# NANO103AE_v1 register map
File version: 1.0
Registers are 32-bit, read-write, reset 0x0 unless marked. A register's access mark holds for its fields unless they carry their own. Offsets are from the block's base; [hi:lo] are bit positions; {n}, {i} and the like mark numbered series; 'fields as' and 'values as' point back to an identical list.

## GPIO — GPIO Register Map
Base 0x50004000
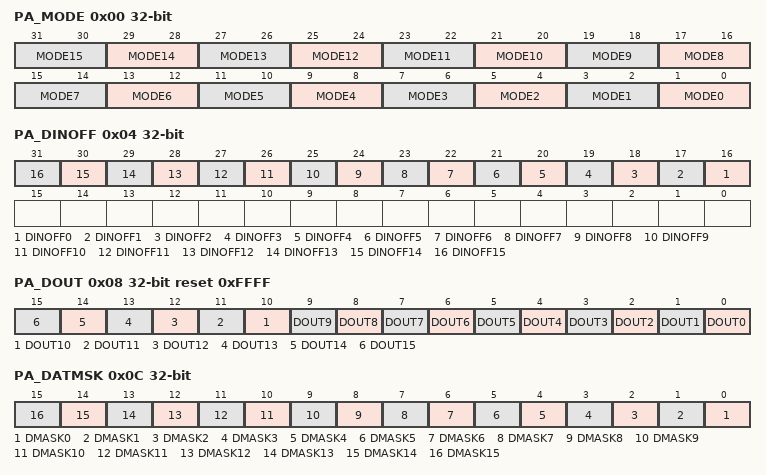
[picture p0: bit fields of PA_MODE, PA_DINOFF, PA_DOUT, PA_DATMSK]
0x00 PA_MODE reset not defined — PA I/O Mode Control
  [all] fields
    0=Px.n is in Input mode; 1=Px.n is in Push-pull Output mode; 2=Px.n is in Open-drain Output mode
  [2n+1:2n] MODE{n} (n=0..15) — Port A-f I/O Pin[N] Mode Control. Determine each I/O mode of Px.n pins. Note2: ThePA.7/PB.12/PC.4/PC.5/PC.12/PC.13/PD.0/PD.1/PD.2/PD.3/PD.4/PD.5/PD.8/PD.9/PD.10/PD.11/PD.12/PD.13/PE.0/PE.1/PE.2/PE.3/PE.4/PE.6/PE.7/PE.8/PE.9/PE.10/PE.11/PE.12/PE.13/PE.14/PE.15/PF.4/PF.5 pin is ignored.
0x04 PA_DINOFF — PA Digital Input Path Disable Control
  [all] fields
    0=Px.n digital input path Enabled; 1=Px.n digital input path Disabled (digital input tied to low)
  [n+16] DINOFF{n} (n=0..15) — Port A-f Pin[N] Digital Input Path Disable Bit. Each of these bits is used to control if the digital input path of corresponding Px.n pin is disabled. If input is analog signal, users can disable Px.n digital input path to avoid input current leakage. Note2: ThePA.7/PB.12/PC.4/PC.5/PC.12/PC.13/PD.0/PD.1/PD.2/PD.3/PD.4/PD.5/PD.8/PD.9/PD.10/PD.11/PD.12/PD.13/PE.0/PE.1/PE.2/PE.3/PE.4/PE.6/PE.7/PE.8/PE.9/PE.10/PE.11/PE.12/PE.13/PE.14/PE.15/PF.4/PF.5 pin is ignored.
0x08 PA_DOUT reset 0xFFFF — PA Data Output Value
  [all] fields
    0=Px.n will drive Low if the Px.n pin is configured as Push-pull output, Open-drain output; 1=Px.n will drive High if the Px.n pin is configured as Push-pull output
  [n] DOUT{n} (n=0..15) — Port A-f Pin[N] Output Value. Each of these bits controls the status of a Px.n pin when the Px.n is configured as Push-pull output, Open-drain output. Note2: ThePA.7/PB.12/PC.4/PC.5/PC.12/PC.13/PD.0/PD.1/PD.2/PD.3/PD.4/PD.5/PD.8/PD.9/PD.10/PD.11/PD.12/PD.13/PE.0/PE.1/PE.2/PE.3/PE.4/PE.6/PE.7/PE.8/PE.9/PE.10/PE.11/PE.12/PE.13/PE.14/PE.15/PF.4/PF.5 pin is ignored.
0x0C PA_DATMSK — PA Data Output Write Mask
  [all] fields
    0=Corresponding DOUT (Px_DOUT[n]) bit can be updated; 1=Corresponding DOUT (Px_DOUT[n]) bit protected
  [n] DMASK{n} (n=0..15) — Port A-f Pin[N] Data Output Write Mask. These bits are used to protect the corresponding DOUT (Px_DOUT[n]) bit. When the DATMSK (Px_DATMSK[n]) bit is set to 1, the corresponding DOUT (Px_DOUT[n]) bit is protected. If the write signal is masked, writing data to the protect bit is ignored. Note3: ThePA.7/PB.12/PC.4/PC.5/PC.12/PC.13/PD.0/PD.1/PD.2/PD.3/PD.4/PD.5/PD.8/PD.9/PD.10/PD.11/PD.12/PD.13/PE.0/PE.1/PE.2/PE.3/PE.4/PE.6/PE.7/PE.8/PE.9/PE.10/PE.11/PE.12/PE.13/PE.14/PE.15/PF.4/PF.5 pin is ignored.
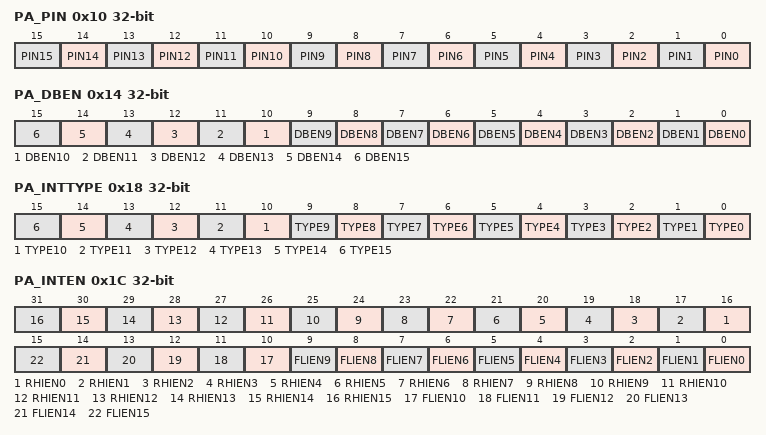
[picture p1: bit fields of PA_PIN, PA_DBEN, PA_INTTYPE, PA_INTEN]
0x10 PA_PIN ro (reset mask 0xFFFF0000) — PA Pin Value
  [n] PIN{n} (n=0..15) — Port A-f Pin[N] Pin Value. Each bit of the register reflects the actual status of the respective Px.n pin. If the bit is 1, it indicates the corresponding pin status is high; else the pin status is low. Note1: Note2: ThePA.7/PB.12/PC.4/PC.5/PC.12/PC.13/PD.0/PD.1/PD.2/PD.3/PD.4/PD.5/PD.8/PD.9/PD.10/PD.11/PD.12/PD.13/PE.0/PE.1/PE.2/PE.3/PE.4/PE.6/PE.7/PE.8/PE.9/PE.10/PE.11/PE.12/PE.13/PE.14/PE.15/PF.4/PF.5 pin is ignored.
0x14 PA_DBEN — PA De-Bounce Enable Control Register
  [all] fields
    0=Px.n de-bounce function Disabled; 1=Px.n de-bounce function Enabled
  [n] DBEN{n} (n=0..15) — Port A-f Pin[N] Input Signal De-bounce Enable Bit. The DBEN[n] bit is used to enable the de-bounce function for each corresponding bit. If the input signal pulse width cannot be sampled by continuous two de-bounce sample cycle, the input signal transition is seen as the signal bounce and will not trigger the interrupt. The de-bounce clock source is controlled by DBCLKSRC (GPIO_DBCTL [4]), one de-bounce sample cycle period is controlled by DBCLKSEL (GPIO_DBCTL [3:0]). Note2: ThePA.7/PB.12/PC.4/PC.5/PC.12/PC.13/PD.0/PD.1/PD.2/PD.3/PD.4/PD.5/PD.8/PD.9/PD.10/PD.11/PD.12/PD.13/PE.0/PE.1/PE.2/PE.3/PE.4/PE.6/PE.7/PE.8/PE.9/PE.10/PE.11/PE.12/PE.13/PE.14/PE.15/PF.4/PF.5 pin is ignored.
0x18 PA_INTTYPE — PA Interrupt Trigger Type Control
  [all] fields
    0=Edge trigger interrupt; 1=Level trigger interrupt
  [n] TYPE{n} (n=0..15) — Port A-f Pin[N] Edge or Level Detection Interrupt Trigger Type Control. TYPE (Px_INTTYPE[n]) bit is used to control the triggered interrupt is by level trigger or by edge trigger. If the interrupt is by edge trigger, the trigger source can be controlled by de-bounce. If the interrupt is by level trigger, the input source is sampled by one HCLK clock and generates the interrupt. Note2: ThePA.7/PB.12/PC.4/PC.5/PC.12/PC.13/PD.0/PD.1/PD.2/PD.3/PD.4/PD.5/PD.8/PD.9/PD.10/PD.11/PD.12/PD.13/PE.0/PE.1/PE.2/PE.3/PE.4/PE.6/PE.7/PE.8/PE.9/PE.10/PE.11/PE.12/PE.13/PE.14/PE.15/PF.4/PF.5 pin is ignored.
0x1C PA_INTEN — PA Interrupt Enable Control Register
  [n+16] RHIEN{n} (n=0..15) — Port A-f Pin[N] Rising Edge or High Level Interrupt Trigger Type Enable Bit. The RHIEN (Px_INTEN[n+16]) bit is used to enable the interrupt for each of the corresponding input Px.n pin. Set bit to 1 also enable the pin wake-up function. When setting the RHIEN (Px_INTEN[n+16]) bit to 1 : If the interrupt is level trigger (TYPE (Px_INTTYPE[n]) bit is set to 1), the input Px.n pin will generate the interrupt while this pin state is at high level. If the interrupt is edge trigger (TYPE (Px_INTTYPE[n]) bit is set to 0), the input Px.n pin will generate the interrupt while this pin state changed from low to high. Note2: ThePA.7/PB.12/PC.4/PC.5/PC.12/PC.13/PD.0/PD.1/PD.2/PD.3/PD.4/PD.5/PD.8/PD.9/PD.10/PD.11/PD.12/PD.13/PE.0/PE.1/PE.2/PE.3/PE.4/PE.6/PE.7/PE.8/PE.9/PE.10/PE.11/PE.12/PE.13/PE.14/PE.15/PF.4/PF.5 pin is ignored.
    0=Px.n level high or low to high interrupt Disabled; 1=Px.n level high or low to high interrupt Enabled
  [n] FLIEN{n} (n=0..15) — Port A-f Pin[N] Falling Edge or Low Level Interrupt Trigger Type Enable Bit. The FLIEN (Px_INTEN[n]) bit is used to enable the interrupt for each of the corresponding input Px.n pin. Set bit to 1 also enable the pin wake-up function. When setting the FLIEN (Px_INTEN[n]) bit to 1 : If the interrupt is level trigger (TYPE (Px_INTTYPE[n]) bit is set to 1), the input Px.n pin will generate the interrupt while this pin state is at low level. If the interrupt is edge trigger(TYPE (Px_INTTYPE[n]) bit is set to 0), the input Px.n pin will generate the interrupt while this pin state changed from high to low. Note2: ThePA.7/PB.12/PC.4/PC.5/PC.12/PC.13/PD.0/PD.1/PD.2/PD.3/PD.4/PD.5/PD.8/PD.9/PD.10/PD.11/PD.12/PD.13/PE.0/PE.1/PE.2/PE.3/PE.4/PE.6/PE.7/PE.8/PE.9/PE.10/PE.11/PE.12/PE.13/PE.14/PE.15/PF.4/PF.5 pin is ignored.
    0=Px.n level low or high to low interrupt Disabled; 1=Px.n level low or high to low interrupt Enabled
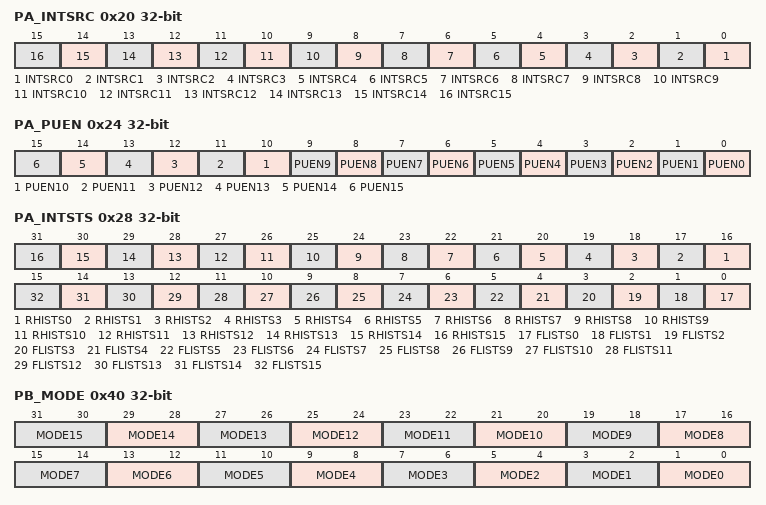
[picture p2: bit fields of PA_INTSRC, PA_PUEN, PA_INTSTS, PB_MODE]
0x20 PA_INTSRC (reset mask 0xFFFF0000) — PA Interrupt Source Flag
  [all] fields
    0=No action. No interrupt at Px.n; 1=Clear the corresponding pending interrupt. Px.n generates an interrupt
  [n] INTSRC{n} (n=0..15) — Port A-f Pin[N] Interrupt Source Flag. Write Operation : Note2: ThePA.7/PB.12/PC.4/PC.5/PC.12/PC.13/PD.0/PD.1/PD.2/PD.3/PD.4/PD.5/PD.8/PD.9/PD.10/PD.11/PD.12/PD.13/PE.0/PE.1/PE.2/PE.3/PE.4/PE.6/PE.7/PE.8/PE.9/PE.10/PE.11/PE.12/PE.13/PE.14/PE.15/PF.4/PF.5 pin is ignored.
0x24 PA_PUEN — PA Pull-Up Enable Control Register
  [all] fields
    0=Px.n internal pull-up resistor Disabled; 1=Px.n internal pull-up resistor Enabled
  [n] PUEN{n} (n=0..15) — Port A-f Pin[N]Pull-up Enable Bit. Read : Note2: ThePA.7/PB.12/PC.4/PC.5/PC.12/PC.13/PD.0/PD.1/PD.2/PD.3/PD.4/PD.5/PD.8/PD.9/PD.10/PD.11/PD.12/PD.13/PE.0/PE.1/PE.2/PE.3/PE.4/PE.6/PE.7/PE.8/PE.9/PE.10/PE.11/PE.12/PE.13/PE.14/PE.15/PF.4/PF.5 pin is ignored.
0x28 PA_INTSTS ro — PA Interrupt Status
  [n+16] RHISTS{n} (n=0..15) — Port A-f Pin[N] Rising Edge Interrupt Status. If the interrupt is rising edge trigger for each of the corresponding input Px.n pin, this bit will be set after interrupt occurred and automatically cleared by interrupt source flag (INTSRC (Px_INTSRC[n])). Note2: The PA.7/PB.12/PC.4/PC.5/PC.12/PC.13/PD.0/PD.1/PD.2/PD.3/PD.4/PD.5/PD.8/PD.9/PD.10/PD.11/PD.12/PD.13/PE.0/PE.1/PE.2/PE.3/PE.4/PE.6/PE.7/PE.8/PE.9/PE.10/PE.11/PE.12/PE.13/PE.14/PE.15/PF.4/PF.5 pin is ignored.
    0=No rising edge interrupt at Px.n; 1=Px.n generates an rising edge interrupt
  [n] FLISTS{n} (n=0..15) — Port A-f Pin[N] Falling Edge Interrupt Status. If the interrupt is falling edge trigger for each of the corresponding input Px.n pin, this bit will be set after interrupt occurred and automatically cleared by interrupt source flag (INTSRC (Px_INTSRC[n])). Note2: The PA.7/PB.12/PC.4/PC.5/PC.12/PC.13/PD.0/PD.1/PD.2/PD.3/PD.4/PD.5/PD.8/PD.9/PD.10/PD.11/PD.12/PD.13/PE.0/PE.1/PE.2/PE.3/PE.4/PE.6/PE.7/PE.8/PE.9/PE.10/PE.11/PE.12/PE.13/PE.14/PE.15/PF.4/PF.5 pin is ignored.
    0=No falling edge interrupt at Px.n; 1=Px.n generates an falling edge interrupt
0x40 PB_MODE reset not defined — PB I/O Mode Control
  fields as PA_MODE
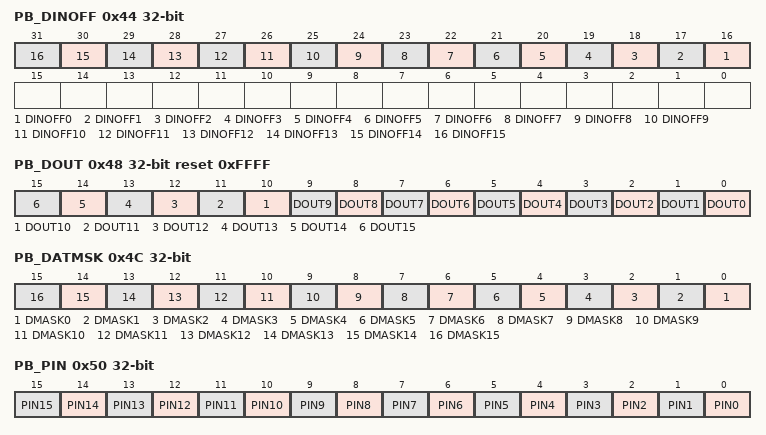
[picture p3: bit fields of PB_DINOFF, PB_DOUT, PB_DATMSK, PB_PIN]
0x44 PB_DINOFF — PB Digital Input Path Disable Control
  fields as PA_DINOFF
0x48 PB_DOUT reset 0xFFFF — PB Data Output Value
  fields as PA_DOUT
0x4C PB_DATMSK — PB Data Output Write Mask
  fields as PA_DATMSK
0x50 PB_PIN ro (reset mask 0xFFFF0000) — PB Pin Value
  fields as PA_PIN
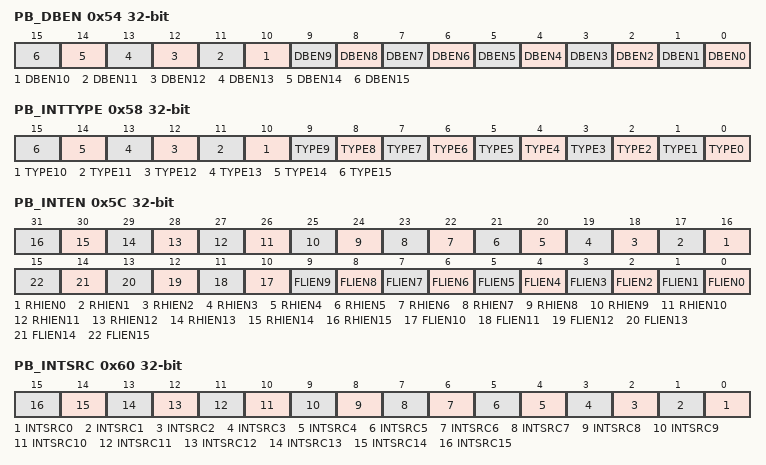
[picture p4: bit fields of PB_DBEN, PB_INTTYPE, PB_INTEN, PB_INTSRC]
0x54 PB_DBEN — PB De-Bounce Enable Control Register
  fields as PA_DBEN
0x58 PB_INTTYPE — PB Interrupt Trigger Type Control
  fields as PA_INTTYPE
0x5C PB_INTEN — PB Interrupt Enable Control Register
  fields as PA_INTEN
0x60 PB_INTSRC (reset mask 0xFFFF0000) — PB Interrupt Source Flag
  fields as PA_INTSRC
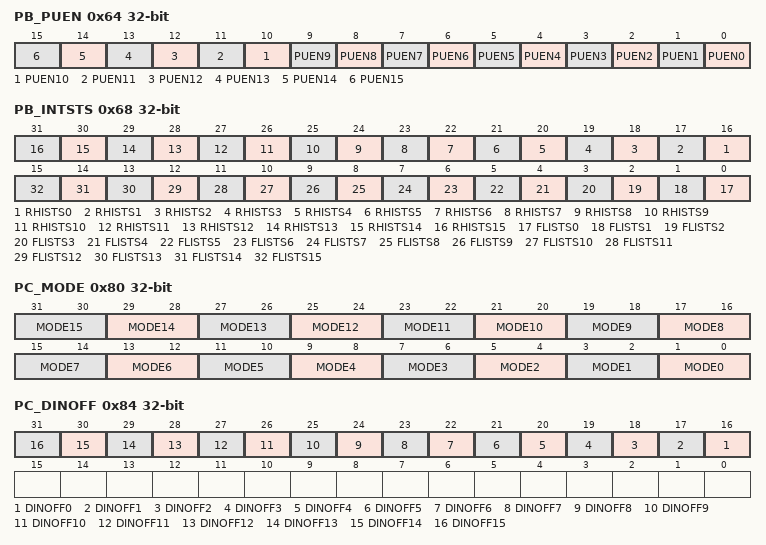
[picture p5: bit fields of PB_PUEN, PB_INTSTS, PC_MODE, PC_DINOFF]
0x64 PB_PUEN — PB Pull-Up Enable Control Register
  fields as PA_PUEN
0x68 PB_INTSTS ro — PB Interrupt Status
  fields as PA_INTSTS
0x80 PC_MODE reset not defined — PC I/O Mode Control
  fields as PA_MODE
0x84 PC_DINOFF — PC Digital Input Path Disable Control
  fields as PA_DINOFF
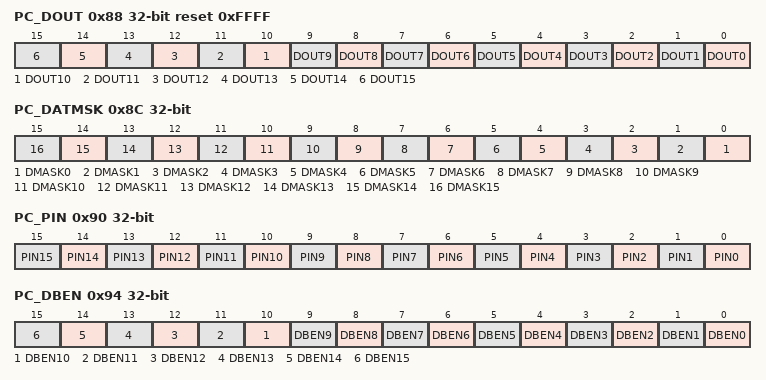
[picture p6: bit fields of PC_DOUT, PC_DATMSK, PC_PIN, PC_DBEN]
0x88 PC_DOUT reset 0xFFFF — PC Data Output Value
  fields as PA_DOUT
0x8C PC_DATMSK — PC Data Output Write Mask
  fields as PA_DATMSK
0x90 PC_PIN ro (reset mask 0xFFFF0000) — PC Pin Value
  fields as PA_PIN
0x94 PC_DBEN — PC De-Bounce Enable Control Register
  fields as PA_DBEN
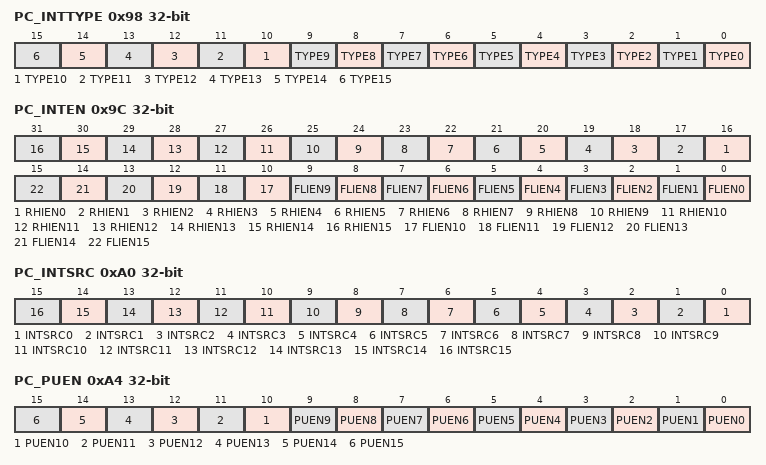
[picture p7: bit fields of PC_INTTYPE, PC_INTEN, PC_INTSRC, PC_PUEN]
0x98 PC_INTTYPE — PC Interrupt Trigger Type Control
  fields as PA_INTTYPE
0x9C PC_INTEN — PC Interrupt Enable Control Register
  fields as PA_INTEN
0xA0 PC_INTSRC (reset mask 0xFFFF0000) — PC Interrupt Source Flag
  fields as PA_INTSRC
0xA4 PC_PUEN — PC Pull-Up Enable Control Register
  fields as PA_PUEN
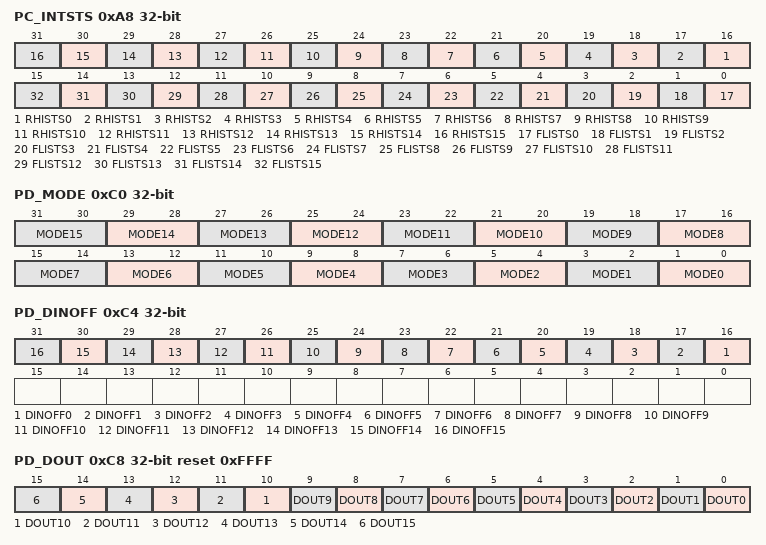
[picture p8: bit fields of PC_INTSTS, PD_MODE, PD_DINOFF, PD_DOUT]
0xA8 PC_INTSTS ro — PC Interrupt Status
  fields as PA_INTSTS
0xC0 PD_MODE reset not defined — PD I/O Mode Control
  fields as PA_MODE
0xC4 PD_DINOFF — PD Digital Input Path Disable Control
  fields as PA_DINOFF
0xC8 PD_DOUT reset 0xFFFF — PD Data Output Value
  fields as PA_DOUT
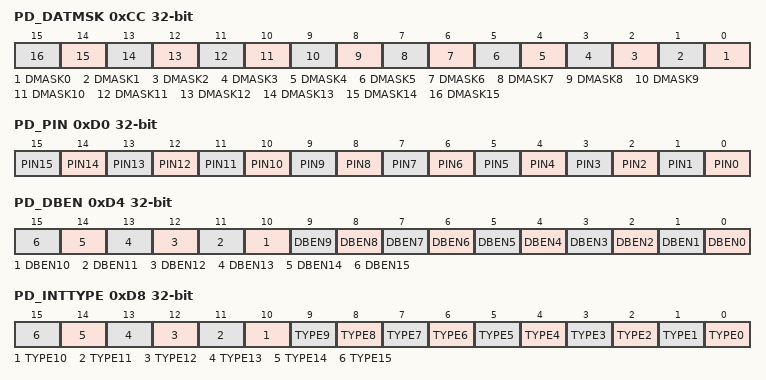
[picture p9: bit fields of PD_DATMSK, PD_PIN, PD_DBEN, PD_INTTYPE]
0xCC PD_DATMSK — PD Data Output Write Mask
  fields as PA_DATMSK
0xD0 PD_PIN ro (reset mask 0xFFFF0000) — PD Pin Value
  fields as PA_PIN
0xD4 PD_DBEN — PD De-Bounce Enable Control Register
  fields as PA_DBEN
0xD8 PD_INTTYPE — PD Interrupt Trigger Type Control
  fields as PA_INTTYPE
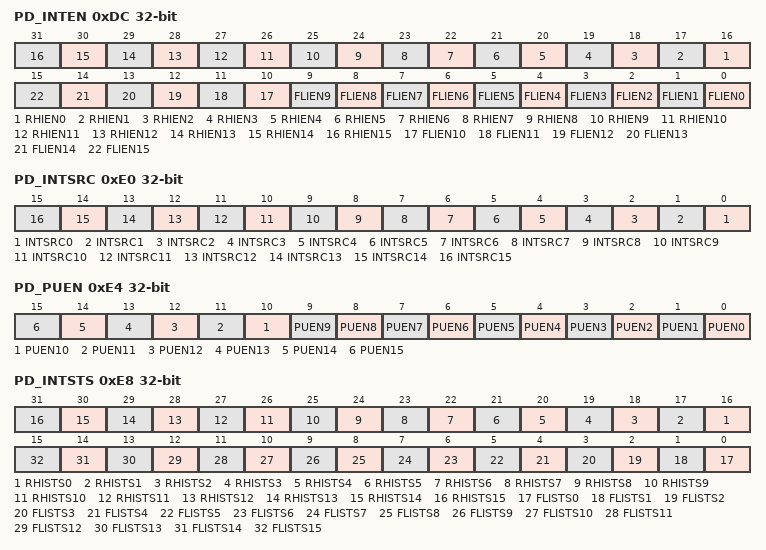
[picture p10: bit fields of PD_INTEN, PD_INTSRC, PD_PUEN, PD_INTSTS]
0xDC PD_INTEN — PD Interrupt Enable Control Register
  fields as PA_INTEN
0xE0 PD_INTSRC (reset mask 0xFFFF0000) — PD Interrupt Source Flag
  fields as PA_INTSRC
0xE4 PD_PUEN — PD Pull-Up Enable Control Register
  fields as PA_PUEN
0xE8 PD_INTSTS ro — PD Interrupt Status
  fields as PA_INTSTS
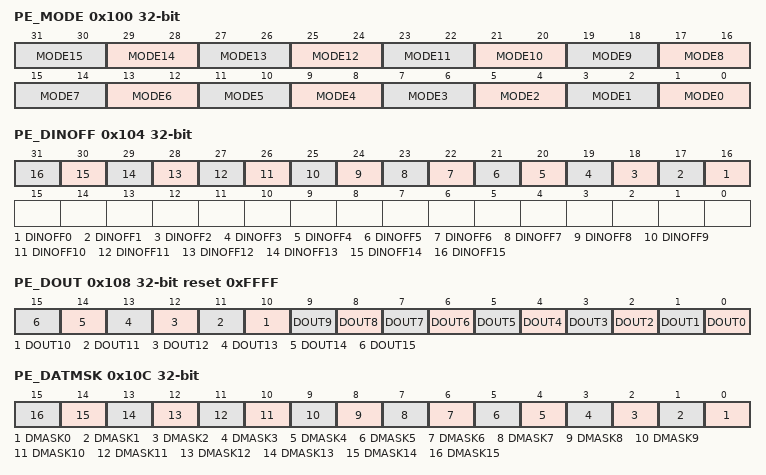
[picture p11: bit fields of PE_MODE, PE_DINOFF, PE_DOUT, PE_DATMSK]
0x100 PE_MODE reset not defined — PE I/O Mode Control
  fields as PA_MODE
0x104 PE_DINOFF — PE Digital Input Path Disable Control
  fields as PA_DINOFF
0x108 PE_DOUT reset 0xFFFF — PE Data Output Value
  fields as PA_DOUT
0x10C PE_DATMSK — PE Data Output Write Mask
  fields as PA_DATMSK
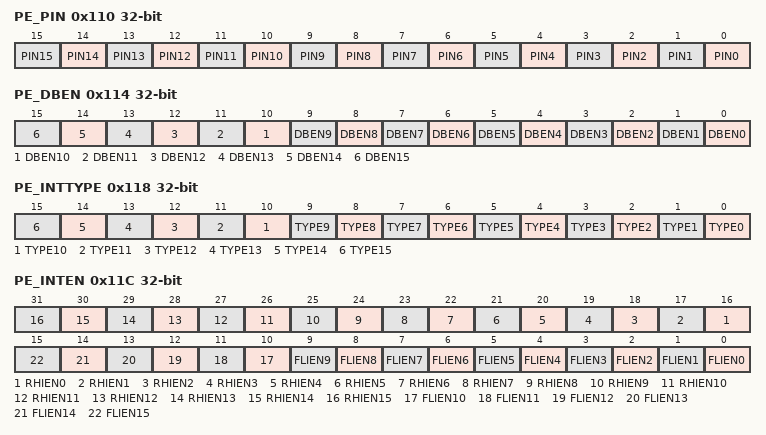
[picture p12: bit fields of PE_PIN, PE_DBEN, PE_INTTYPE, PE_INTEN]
0x110 PE_PIN ro (reset mask 0xFFFF0000) — PE Pin Value
  fields as PA_PIN
0x114 PE_DBEN — PE De-Bounce Enable Control Register
  fields as PA_DBEN
0x118 PE_INTTYPE — PE Interrupt Trigger Type Control
  fields as PA_INTTYPE
0x11C PE_INTEN — PE Interrupt Enable Control Register
  fields as PA_INTEN
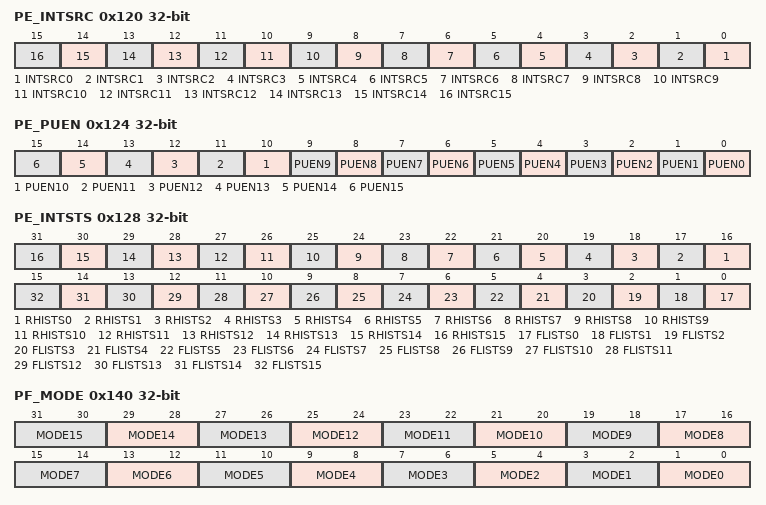
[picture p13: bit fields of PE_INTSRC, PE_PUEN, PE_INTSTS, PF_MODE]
0x120 PE_INTSRC (reset mask 0xFFFF0000) — PE Interrupt Source Flag
  fields as PA_INTSRC
0x124 PE_PUEN — PE Pull-Up Enable Control Register
  fields as PA_PUEN
0x128 PE_INTSTS ro — PE Interrupt Status
  fields as PA_INTSTS
0x140 PF_MODE reset not defined — PF I/O Mode Control
  fields as PA_MODE
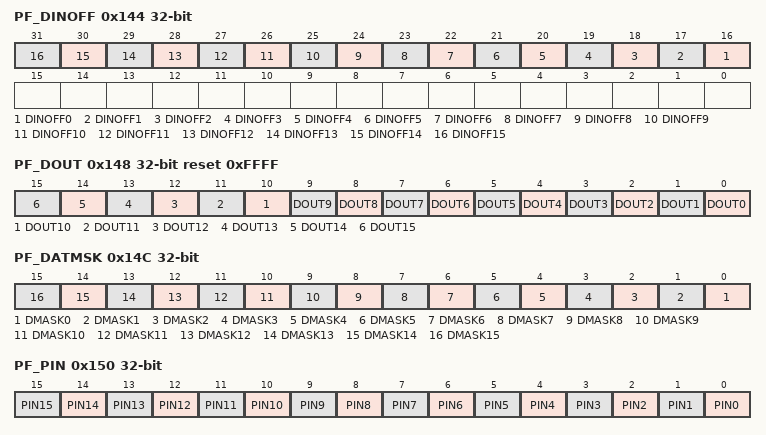
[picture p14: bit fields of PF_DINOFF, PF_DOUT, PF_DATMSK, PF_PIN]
0x144 PF_DINOFF — PF Digital Input Path Disable Control
  fields as PA_DINOFF
0x148 PF_DOUT reset 0xFFFF — PF Data Output Value
  fields as PA_DOUT
0x14C PF_DATMSK — PF Data Output Write Mask
  fields as PA_DATMSK
0x150 PF_PIN ro (reset mask 0xFFFF0000) — PF Pin Value
  fields as PA_PIN
0x154 PF_DBEN — PF De-Bounce Enable Control Register
  fields as PA_DBEN
0x158 PF_INTTYPE — PF Interrupt Trigger Type Control
  fields as PA_INTTYPE
0x15C PF_INTEN — PF Interrupt Enable Control Register
  fields as PA_INTEN
0x160 PF_INTSRC (reset mask 0xFFFF0000) — PF Interrupt Source Flag
  fields as PA_INTSRC
0x164 PF_PUEN — PF Pull-Up Enable Control Register
  fields as PA_PUEN
0x168 PF_INTSTS ro — PF Interrupt Status
  fields as PA_INTSTS
0x180 GPIO_DBCTL — Interrupt De-bounce Control Register
  [5] ICLKON — Interrupt Clock on Mode. Note:It is recommended to disable this bit to save system power if no special application concern.
    0=Edge detection circuit is active only if I/O pin corresponding RHIEN (Px_INTEN[n+16])/FLIEN (Px_INTEN[n]) bit is set to 1; 1=All I/O pins edge detection circuit is always active after reset
  [4] DBCLKSRC — De-bounce Counter Clock Source Selection
    0=De-bounce counter clock source is the HCLK; 1=De-bounce counter clock source is the 10 kHz internal low speed RC oscillator (LIRC)
  [3:0] DBCLKSEL — De-bounce Sampling Cycle Selection
    0=Sample interrupt input once per 1 clocks; 1=Sample interrupt input once per 2 clocks; 2=Sample interrupt input once per 4 clocks; 3=Sample interrupt input once per 8 clocks; 4=Sample interrupt input once per 16 clocks; 5=Sample interrupt input once per 32 clocks; 6=Sample interrupt input once per 64 clocks; 7=Sample interrupt input once per 128 clocks; 8=Sample interrupt input once per 256 clocks; 9=Sample interrupt input once per 2*256 clocks; 10=Sample interrupt input once per 4*256 clocks; 11=Sample interrupt input once per 8*256 clocks; 12=Sample interrupt input once per 16*256 clocks; 13=Sample interrupt input once per 32*256 clocks; 14=Sample interrupt input once per 64*256 clocks; 15=Sample interrupt input once per 128*256 clocks
0x200 PA0_PDIO (reset mask 0xFFFFFFF0) — GPIO PA.0 Pin Data Input/Output Register
  [0] PDIO — GPIO Px.N Pin Data Input/Output. Writing this bit can control one GPIO pin output value. Note3: ThePA.7/PB.12/PC.4/PC.5/PC.12/PC.13/PD.0/PD.1/PD.2/PD.3/PD.4/PD.5/PD.8/PD.9/PD.10/PD.11/PD.12/PD.13/PE.0/PE.1/PE.2/PE.3/PE.4/PE.6/PE.7/PE.8/PE.9/PE.10/PE.11/PE.12/PE.13/PE.14/PE.15/PF.4/PF.5 pin is ignored.
    0=Corresponding GPIO pin set to low; 1=Corresponding GPIO pin set to high
0x204 PA1_PDIO (reset mask 0xFFFFFFF0) — GPIO PA.1 Pin Data Input/Output Register
  fields as PA0_PDIO
0x208 PA2_PDIO (reset mask 0xFFFFFFF0) — GPIO PA.2 Pin Data Input/Output Register
  fields as PA0_PDIO
0x20C PA3_PDIO (reset mask 0xFFFFFFF0) — GPIO PA.3 Pin Data Input/Output Register
  fields as PA0_PDIO
0x210 PA4_PDIO (reset mask 0xFFFFFFF0) — GPIO PA.4 Pin Data Input/Output Register
  fields as PA0_PDIO
0x214 PA5_PDIO (reset mask 0xFFFFFFF0) — GPIO PA.5 Pin Data Input/Output Register
  fields as PA0_PDIO
0x218 PA6_PDIO (reset mask 0xFFFFFFF0) — GPIO PA.6 Pin Data Input/Output Register
  fields as PA0_PDIO
0x21C PA7_PDIO (reset mask 0xFFFFFFF0) — GPIO PA.7 Pin Data Input/Output Register
  fields as PA0_PDIO
0x220 PA8_PDIO (reset mask 0xFFFFFFF0) — GPIO PA.8 Pin Data Input/Output Register
  fields as PA0_PDIO
0x224 PA9_PDIO (reset mask 0xFFFFFFF0) — GPIO PA.9 Pin Data Input/Output Register
  fields as PA0_PDIO
0x228 PA10_PDIO (reset mask 0xFFFFFFF0) — GPIO PA.10 Pin Data Input/Output Register
  fields as PA0_PDIO
0x22C PA11_PDIO (reset mask 0xFFFFFFF0) — GPIO PA.11 Pin Data Input/Output Register
  fields as PA0_PDIO
0x230 PA12_PDIO (reset mask 0xFFFFFFF0) — GPIO PA.12 Pin Data Input/Output Register
  fields as PA0_PDIO
0x234 PA13_PDIO (reset mask 0xFFFFFFF0) — GPIO PA.13 Pin Data Input/Output Register
  fields as PA0_PDIO
0x238 PA14_PDIO (reset mask 0xFFFFFFF0) — GPIO PA.14 Pin Data Input/Output Register
  fields as PA0_PDIO
0x23C PA15_PDIO (reset mask 0xFFFFFFF0) — GPIO PA.15 Pin Data Input/Output Register
  fields as PA0_PDIO
0x240 PB0_PDIO (reset mask 0xFFFFFFF0) — GPIO PB.0 Pin Data Input/Output Register
  fields as PA0_PDIO
0x244 PB1_PDIO (reset mask 0xFFFFFFF0) — GPIO PB.1 Pin Data Input/Output Register
  fields as PA0_PDIO
0x248 PB2_PDIO (reset mask 0xFFFFFFF0) — GPIO PB.2 Pin Data Input/Output Register
  fields as PA0_PDIO
0x24C PB3_PDIO (reset mask 0xFFFFFFF0) — GPIO PB.3 Pin Data Input/Output Register
  fields as PA0_PDIO
0x250 PB4_PDIO (reset mask 0xFFFFFFF0) — GPIO PB.4 Pin Data Input/Output Register
  fields as PA0_PDIO
0x254 PB5_PDIO (reset mask 0xFFFFFFF0) — GPIO PB.5 Pin Data Input/Output Register
  fields as PA0_PDIO
0x258 PB6_PDIO (reset mask 0xFFFFFFF0) — GPIO PB.6 Pin Data Input/Output Register
  fields as PA0_PDIO
0x25C PB7_PDIO (reset mask 0xFFFFFFF0) — GPIO PB.7 Pin Data Input/Output Register
  fields as PA0_PDIO
0x260 PB8_PDIO (reset mask 0xFFFFFFF0) — GPIO PB.8 Pin Data Input/Output Register
  fields as PA0_PDIO
0x264 PB9_PDIO (reset mask 0xFFFFFFF0) — GPIO PB.9 Pin Data Input/Output Register
  fields as PA0_PDIO
0x268 PB10_PDIO (reset mask 0xFFFFFFF0) — GPIO PB.10 Pin Data Input/Output Register
  fields as PA0_PDIO
0x26C PB11_PDIO (reset mask 0xFFFFFFF0) — GPIO PB.11 Pin Data Input/Output Register
  fields as PA0_PDIO
0x270 PB12_PDIO (reset mask 0xFFFFFFF0) — GPIO PB.12 Pin Data Input/Output Register
  fields as PA0_PDIO
0x274 PB13_PDIO (reset mask 0xFFFFFFF0) — GPIO PB.13 Pin Data Input/Output Register
  fields as PA0_PDIO
0x278 PB14_PDIO (reset mask 0xFFFFFFF0) — GPIO PB.14 Pin Data Input/Output Register
  fields as PA0_PDIO
0x27C PB15_PDIO (reset mask 0xFFFFFFF0) — GPIO PB.15 Pin Data Input/Output Register
  fields as PA0_PDIO
0x280 PC0_PDIO (reset mask 0xFFFFFFF0) — GPIO PC.0 Pin Data Input/Output Register
  fields as PA0_PDIO
0x284 PC1_PDIO (reset mask 0xFFFFFFF0) — GPIO PC.1 Pin Data Input/Output Register
  fields as PA0_PDIO
0x288 PC2_PDIO (reset mask 0xFFFFFFF0) — GPIO PC.2 Pin Data Input/Output Register
  fields as PA0_PDIO
0x28C PC3_PDIO (reset mask 0xFFFFFFF0) — GPIO PC.3 Pin Data Input/Output Register
  fields as PA0_PDIO
0x290 PC4_PDIO (reset mask 0xFFFFFFF0) — GPIO PC.4 Pin Data Input/Output Register
  fields as PA0_PDIO
0x294 PC5_PDIO (reset mask 0xFFFFFFF0) — GPIO PC.5 Pin Data Input/Output Register
  fields as PA0_PDIO
0x298 PC6_PDIO (reset mask 0xFFFFFFF0) — GPIO PC.6 Pin Data Input/Output Register
  fields as PA0_PDIO
0x29C PC7_PDIO (reset mask 0xFFFFFFF0) — GPIO PC.7 Pin Data Input/Output Register
  fields as PA0_PDIO
0x2A0 PC8_PDIO (reset mask 0xFFFFFFF0) — GPIO PC.8 Pin Data Input/Output Register
  fields as PA0_PDIO
0x2A4 PC9_PDIO (reset mask 0xFFFFFFF0) — GPIO PC.9 Pin Data Input/Output Register
  fields as PA0_PDIO
0x2A8 PC10_PDIO (reset mask 0xFFFFFFF0) — GPIO PC.10 Pin Data Input/Output Register
  fields as PA0_PDIO
0x2AC PC11_PDIO (reset mask 0xFFFFFFF0) — GPIO PC.11 Pin Data Input/Output Register
  fields as PA0_PDIO
0x2B0 PC12_PDIO (reset mask 0xFFFFFFF0) — GPIO PC.12 Pin Data Input/Output Register
  fields as PA0_PDIO
0x2B4 PC13_PDIO (reset mask 0xFFFFFFF0) — GPIO PC.13 Pin Data Input/Output Register
  fields as PA0_PDIO
0x2B8 PC14_PDIO (reset mask 0xFFFFFFF0) — GPIO PC.14 Pin Data Input/Output Register
  fields as PA0_PDIO
0x2BC PC15_PDIO (reset mask 0xFFFFFFF0) — GPIO PC.15 Pin Data Input/Output Register
  fields as PA0_PDIO
0x2C0 PD0_PDIO (reset mask 0xFFFFFFF0) — GPIO PD.0 Pin Data Input/Output Register
  fields as PA0_PDIO
0x2C4 PD1_PDIO (reset mask 0xFFFFFFF0) — GPIO PD.1 Pin Data Input/Output Register
  fields as PA0_PDIO
0x2C8 PD2_PDIO (reset mask 0xFFFFFFF0) — GPIO PD.2 Pin Data Input/Output Register
  fields as PA0_PDIO
0x2CC PD3_PDIO (reset mask 0xFFFFFFF0) — GPIO PD.3 Pin Data Input/Output Register
  fields as PA0_PDIO
0x2D0 PD4_PDIO (reset mask 0xFFFFFFF0) — GPIO PD.4 Pin Data Input/Output Register
  fields as PA0_PDIO
0x2D4 PD5_PDIO (reset mask 0xFFFFFFF0) — GPIO PD.5 Pin Data Input/Output Register
  fields as PA0_PDIO
0x2D8 PD6_PDIO (reset mask 0xFFFFFFF0) — GPIO PD.6 Pin Data Input/Output Register
  fields as PA0_PDIO
0x2DC PD7_PDIO (reset mask 0xFFFFFFF0) — GPIO PD.7 Pin Data Input/Output Register
  fields as PA0_PDIO
0x2E0 PD8_PDIO (reset mask 0xFFFFFFF0) — GPIO PD.8 Pin Data Input/Output Register
  fields as PA0_PDIO
0x2E4 PD9_PDIO (reset mask 0xFFFFFFF0) — GPIO PD.9 Pin Data Input/Output Register
  fields as PA0_PDIO
0x2E8 PD10_PDIO (reset mask 0xFFFFFFF0) — GPIO PD.10 Pin Data Input/Output Register
  fields as PA0_PDIO
0x2EC PD11_PDIO (reset mask 0xFFFFFFF0) — GPIO PD.11 Pin Data Input/Output Register
  fields as PA0_PDIO
0x2F0 PD12_PDIO (reset mask 0xFFFFFFF0) — GPIO PD.12 Pin Data Input/Output Register
  fields as PA0_PDIO
0x2F4 PD13_PDIO (reset mask 0xFFFFFFF0) — GPIO PD.13 Pin Data Input/Output Register
  fields as PA0_PDIO
0x2F8 PD14_PDIO (reset mask 0xFFFFFFF0) — GPIO PD.14 Pin Data Input/Output Register
  fields as PA0_PDIO
0x2FC PD15_PDIO (reset mask 0xFFFFFFF0) — GPIO PD.15 Pin Data Input/Output Register
  fields as PA0_PDIO
0x300 PE0_PDIO (reset mask 0xFFFFFFF0) — GPIO PE.0 Pin Data Input/Output Register
  fields as PA0_PDIO
0x304 PE1_PDIO (reset mask 0xFFFFFFF0) — GPIO PE.1 Pin Data Input/Output Register
  fields as PA0_PDIO
0x308 PE2_PDIO (reset mask 0xFFFFFFF0) — GPIO PE.2 Pin Data Input/Output Register
  fields as PA0_PDIO
0x30C PE3_PDIO (reset mask 0xFFFFFFF0) — GPIO PE.3 Pin Data Input/Output Register
  fields as PA0_PDIO
0x310 PE4_PDIO (reset mask 0xFFFFFFF0) — GPIO PE.4 Pin Data Input/Output Register
  fields as PA0_PDIO
0x314 PE5_PDIO (reset mask 0xFFFFFFF0) — GPIO PE.5 Pin Data Input/Output Register
  fields as PA0_PDIO
0x318 PE6_PDIO (reset mask 0xFFFFFFF0) — GPIO PE.6 Pin Data Input/Output Register
  fields as PA0_PDIO
0x31C PE7_PDIO (reset mask 0xFFFFFFF0) — GPIO PE.7 Pin Data Input/Output Register
  fields as PA0_PDIO
0x320 PE8_PDIO (reset mask 0xFFFFFFF0) — GPIO PE.8 Pin Data Input/Output Register
  fields as PA0_PDIO
0x324 PE9_PDIO (reset mask 0xFFFFFFF0) — GPIO PE.9 Pin Data Input/Output Register
  fields as PA0_PDIO
0x328 PE10_PDIO (reset mask 0xFFFFFFF0) — GPIO PE.10 Pin Data Input/Output Register
  fields as PA0_PDIO
0x32C PE11_PDIO (reset mask 0xFFFFFFF0) — GPIO PE.11 Pin Data Input/Output Register
  fields as PA0_PDIO
0x330 PE12_PDIO (reset mask 0xFFFFFFF0) — GPIO PE.12 Pin Data Input/Output Register
  fields as PA0_PDIO
0x334 PE13_PDIO (reset mask 0xFFFFFFF0) — GPIO PE.13 Pin Data Input/Output Register
  fields as PA0_PDIO
0x338 PE14_PDIO (reset mask 0xFFFFFFF0) — GPIO PE.14 Pin Data Input/Output Register
  fields as PA0_PDIO
0x340 PF0_PDIO (reset mask 0xFFFFFFF0) — GPIO PF.0 Pin Data Input/Output Register
  fields as PA0_PDIO
0x344 PF1_PDIO (reset mask 0xFFFFFFF0) — GPIO PF.1 Pin Data Input/Output Register
  fields as PA0_PDIO
0x348 PF2_PDIO (reset mask 0xFFFFFFF0) — GPIO PF.2 Pin Data Input/Output Register
  fields as PA0_PDIO
0x34C PF3_PDIO (reset mask 0xFFFFFFF0) — GPIO PF.3 Pin Data Input/Output Register
  fields as PA0_PDIO
0x350 PF4_PDIO (reset mask 0xFFFFFFF0) — GPIO PF.4 Pin Data Input/Output Register
  fields as PA0_PDIO
0x354 PF5_PDIO (reset mask 0xFFFFFFF0) — GPIO PF.5 Pin Data Input/Output Register
  fields as PA0_PDIO
0x358 PF6_PDIO (reset mask 0xFFFFFFF0) — GPIO PF.6 Pin Data Input/Output Register
  fields as PA0_PDIO
0x35C PF7_PDIO (reset mask 0xFFFFFFF0) — GPIO PF.7 Pin Data Input/Output Register
  fields as PA0_PDIO
